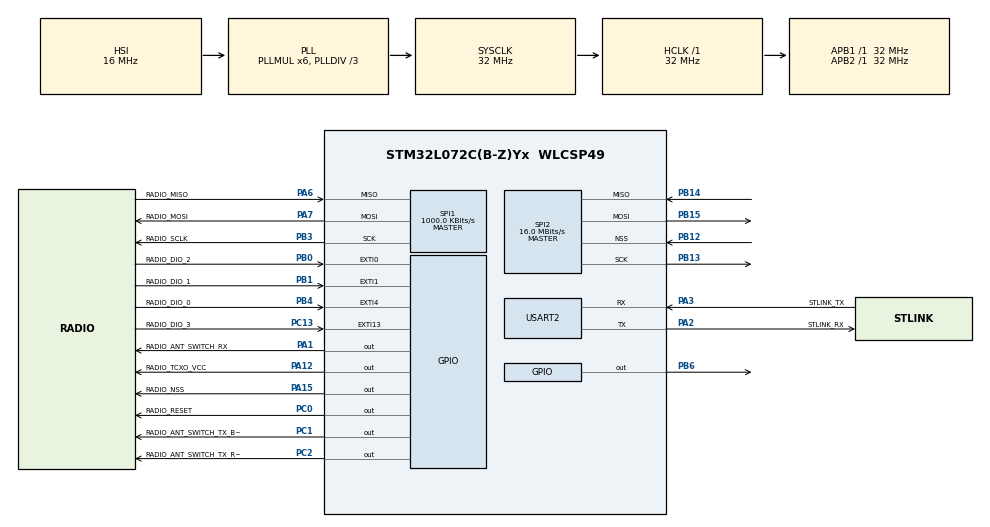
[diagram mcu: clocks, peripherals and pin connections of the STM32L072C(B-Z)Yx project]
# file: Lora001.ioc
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Mcu.Family=STM32L0
Mcu.Name=STM32L072C(B-Z)Yx
Mcu.Package=WLCSP49
NVIC.EXTI0_1_IRQn=true\:0\:0\:false\:false\:true\:true
NVIC.EXTI4_15_IRQn=true\:0\:0\:false\:false\:true\:true
NVIC.RTC_IRQn=true\:0\:0\:false\:false\:true\:true
NVIC.USART2_IRQn=true\:0\:0\:false\:false\:true\:true
PA1.GPIO_Label=RADIO_ANT_SWITCH_RX
PA1.GPIO_Speed=GPIO_SPEED_FREQ_HIGH
PA1.PinState=GPIO_PIN_RESET
PA1.Signal=GPIO_Output
PA12.GPIO_Label=RADIO_TCXO_VCC
PA12.GPIO_Speed=GPIO_SPEED_FREQ_HIGH
PA12.Signal=GPIO_Output
PA15.GPIO_Label=RADIO_NSS
PA15.GPIO_Speed=GPIO_SPEED_FREQ_HIGH
PA15.Signal=GPIO_Output
PA2.GPIO_Label=STLINK_RX
PA2.Mode=Asynchronous
PA2.Signal=USART2_TX
PA3.GPIO_Label=STLINK_TX
PA3.Mode=Asynchronous
PA3.Signal=USART2_RX
PA6.GPIO_Label=RADIO_MISO
PA6.Mode=Full_Duplex_Master
PA6.Signal=SPI1_MISO
PA7.GPIO_Label=RADIO_MOSI
PA7.Mode=Full_Duplex_Master
PA7.Signal=SPI1_MOSI
PB0.GPIO_Label=RADIO_DIO_2
PB0.Signal=GPXTI0
PB1.GPIO_Label=RADIO_DIO_1
PB1.Signal=GPXTI1
PB12.Mode=NSS_Signal_Hard_Input
PB12.Signal=SPI2_NSS
PB13.Mode=Full_Duplex_Master
PB13.Signal=SPI2_SCK
PB14.Mode=Full_Duplex_Master
PB14.Signal=SPI2_MISO
PB15.Mode=Full_Duplex_Master
PB15.Signal=SPI2_MOSI
PB3.GPIO_Label=RADIO_SCLK
PB3.Mode=Full_Duplex_Master
PB3.Signal=SPI1_SCK
PB4.GPIO_Label=RADIO_DIO_0
PB4.Signal=GPXTI4
PB6.Signal=GPIO_Output
PC0.GPIO_Label=RADIO_RESET
PC0.GPIO_Speed=GPIO_SPEED_FREQ_HIGH
PC0.Signal=GPIO_Output
PC1.GPIO_Label=RADIO_ANT_SWITCH_TX_BOOST
PC1.GPIO_Speed=GPIO_SPEED_FREQ_HIGH
PC1.Signal=GPIO_Output
PC13.GPIO_Label=RADIO_DIO_3
PC13.Signal=GPXTI13
PC2.GPIO_Label=RADIO_ANT_SWITCH_TX_RFO
PC2.GPIO_Speed=GPIO_SPEED_FREQ_HIGH
PC2.Signal=GPIO_Output
PH0-OSC_IN.Signal=RCC_OSC_IN
PH1-OSC_OUT.Signal=RCC_OSC_OUT
ProjectManager.HeapSize=0x200
ProjectManager.StackSize=0x400
ProjectManager.TargetToolchain=TrueSTUDIO
RCC.AHBFreq_Value=32000000
RCC.APB1Freq_Value=32000000
RCC.APB1TimFreq_Value=32000000
RCC.APB2Freq_Value=32000000
RCC.APB2TimFreq_Value=32000000
RCC.HCLKFreq_Value=32000000
RCC.HSE_VALUE=8000000
RCC.HSI16_VALUE=16000000
RCC.HSI48_VALUE=48000000
RCC.HSI_VALUE=16000000
RCC.LSE_VALUE=32768
RCC.MSI_VALUE=2097000
RCC.PLLDIV=RCC_PLLDIV_3
RCC.PLLMUL=RCC_PLLMUL_6
RCC.SYSCLKFreq_VALUE=32000000
RCC.SYSCLKSource=RCC_SYSCLKSOURCE_PLLCLK
RCC.VCOOutputFreq_Value=96000000
RTC.Alarm-Alarm\ A=RTC_ALARM_A
RTC.AlarmSubSecondMask-Alarm\ A=RTC_ALARMSUBSECONDMASK_NONE
RTC.AsynchPrediv=31
RTC.Format=RTC_FORMAT_BIN
RTC.SynchPrediv=1023
SPI1.BaudRatePrescaler=SPI_BAUDRATEPRESCALER_32
SPI1.CalculateBaudRate=1000.0 KBits/s
SPI1.Direction=SPI_DIRECTION_2LINES
SPI1.Mode=SPI_MODE_MASTER
SPI1.VirtualType=VM_MASTER
SPI2.BaudRatePrescaler=SPI_BAUDRATEPRESCALER_2
SPI2.CalculateBaudRate=16.0 MBits/s
SPI2.Direction=SPI_DIRECTION_2LINES
SPI2.Mode=SPI_MODE_MASTER
SPI2.VirtualNSS=VM_NSSHARD
SPI2.VirtualType=VM_MASTER
USART2.VirtualMode-Asynchronous=VM_ASYNC
VP_RTC_VS_RTC_Activate.Mode=RTC_Enabled
VP_RTC_VS_RTC_Alarm_A_Intern.Mode=Alarm A
VP_RTC_VS_RTC_Calendar.Mode=RTC_Calendar
board=B-L072Z-LRWAN1

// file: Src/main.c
/* USER CODE BEGIN Header */
/**
  ******************************************************************************
  * @file           : main.c
  * @brief          : Main program body
  ******************************************************************************
  ** This notice applies to any and all portions of this file
  * that are not between comment pairs USER CODE BEGIN and
  * USER CODE END. Other portions of this file, whether
  * inserted by the user or by software development tools
  * are owned by their respective copyright owners.
  *
  * COPYRIGHT(c) 2019 STMicroelectronics
  *
  * Redistribution and use in source and binary forms, with or without modification,
  * are permitted provided that the following conditions are met:
  *   1. Redistributions of source code must retain the above copyright notice,
  *      this list of conditions and the following disclaimer.
  *   2. Redistributions in binary form must reproduce the above copyright notice,
  *      this list of conditions and the following disclaimer in the documentation
  *      and/or other materials provided with the distribution.
  *   3. Neither the name of STMicroelectronics nor the names of its contributors
  *      may be used to endorse or promote products derived from this software
  *      without specific prior written permission.
  *
  * THIS SOFTWARE IS PROVIDED BY THE COPYRIGHT HOLDERS AND CONTRIBUTORS "AS IS"
  * AND ANY EXPRESS OR IMPLIED WARRANTIES, INCLUDING, BUT NOT LIMITED TO, THE
  * IMPLIED WARRANTIES OF MERCHANTABILITY AND FITNESS FOR A PARTICULAR PURPOSE ARE
  * DISCLAIMED. IN NO EVENT SHALL THE COPYRIGHT HOLDER OR CONTRIBUTORS BE LIABLE
  * FOR ANY DIRECT, INDIRECT, INCIDENTAL, SPECIAL, EXEMPLARY, OR CONSEQUENTIAL
  * DAMAGES (INCLUDING, BUT NOT LIMITED TO, PROCUREMENT OF SUBSTITUTE GOODS OR
  * SERVICES; LOSS OF USE, DATA, OR PROFITS; OR BUSINESS INTERRUPTION) HOWEVER
  * CAUSED AND ON ANY THEORY OF LIABILITY, WHETHER IN CONTRACT, STRICT LIABILITY,
  * OR TORT (INCLUDING NEGLIGENCE OR OTHERWISE) ARISING IN ANY WAY OUT OF THE USE
  * OF THIS SOFTWARE, EVEN IF ADVISED OF THE POSSIBILITY OF SUCH DAMAGE.
  *
  ******************************************************************************
  */
/* USER CODE END Header */

#include "main.h"
#include "rtc.h"
#include "spi.h"
#include "usart.h"
#include "gpio.h"

void SystemClock_Config(void);

/* USER CODE BEGIN 0 */
int a = 1;
/* USER CODE END 0 */

int main(void)
{

  /* MCU Configuration--------------------------------------------------------*/

  /* Reset of all peripherals, Initializes the Flash interface and the Systick. */
  HAL_Init();

  /* Configure the system clock */
  SystemClock_Config();

  /* Initialize all configured peripherals */
  MX_GPIO_Init();
  MX_RTC_Init();
  MX_SPI1_Init();
  MX_SPI2_Init();
  MX_USART2_UART_Init();

  /* Infinite loop */
  while (1)
  {
	  HAL_GPIO_TogglePin(GPIOB, GPIO_PIN_6);
	  HAL_Delay(100);
  }
}

void SystemClock_Config(void)
{
  RCC_OscInitTypeDef RCC_OscInitStruct = {0};
  RCC_ClkInitTypeDef RCC_ClkInitStruct = {0};
  RCC_PeriphCLKInitTypeDef PeriphClkInit = {0};

  /**Configure the main internal regulator output voltage
  */
  __HAL_PWR_VOLTAGESCALING_CONFIG(PWR_REGULATOR_VOLTAGE_SCALE1);
  /**Initializes the CPU, AHB and APB busses clocks
  */
  RCC_OscInitStruct.OscillatorType = RCC_OSCILLATORTYPE_HSI|RCC_OSCILLATORTYPE_LSI;
  RCC_OscInitStruct.HSIState = RCC_HSI_ON;
  RCC_OscInitStruct.HSICalibrationValue = RCC_HSICALIBRATION_DEFAULT;
  RCC_OscInitStruct.LSIState = RCC_LSI_ON;
  RCC_OscInitStruct.PLL.PLLState = RCC_PLL_ON;
  RCC_OscInitStruct.PLL.PLLSource = RCC_PLLSOURCE_HSI;
  RCC_OscInitStruct.PLL.PLLMUL = RCC_PLLMUL_6;
  RCC_OscInitStruct.PLL.PLLDIV = RCC_PLLDIV_3;
  if (HAL_RCC_OscConfig(&RCC_OscInitStruct) != HAL_OK)
  {
    Error_Handler();
  }
  /**Initializes the CPU, AHB and APB busses clocks
  */
  RCC_ClkInitStruct.ClockType = RCC_CLOCKTYPE_HCLK|RCC_CLOCKTYPE_SYSCLK
                              |RCC_CLOCKTYPE_PCLK1|RCC_CLOCKTYPE_PCLK2;
  RCC_ClkInitStruct.SYSCLKSource = RCC_SYSCLKSOURCE_PLLCLK;
  RCC_ClkInitStruct.AHBCLKDivider = RCC_SYSCLK_DIV1;
  RCC_ClkInitStruct.APB1CLKDivider = RCC_HCLK_DIV1;
  RCC_ClkInitStruct.APB2CLKDivider = RCC_HCLK_DIV1;

  if (HAL_RCC_ClockConfig(&RCC_ClkInitStruct, FLASH_LATENCY_1) != HAL_OK)
  {
    Error_Handler();
  }
  PeriphClkInit.PeriphClockSelection = RCC_PERIPHCLK_USART2|RCC_PERIPHCLK_RTC;
  PeriphClkInit.Usart2ClockSelection = RCC_USART2CLKSOURCE_PCLK1;
  PeriphClkInit.RTCClockSelection = RCC_RTCCLKSOURCE_LSI;
  if (HAL_RCCEx_PeriphCLKConfig(&PeriphClkInit) != HAL_OK)
  {
    Error_Handler();
  }
}

void Error_Handler(void)
{
}

/************************ (C) COPYRIGHT STMicroelectronics *****END OF FILE****/
